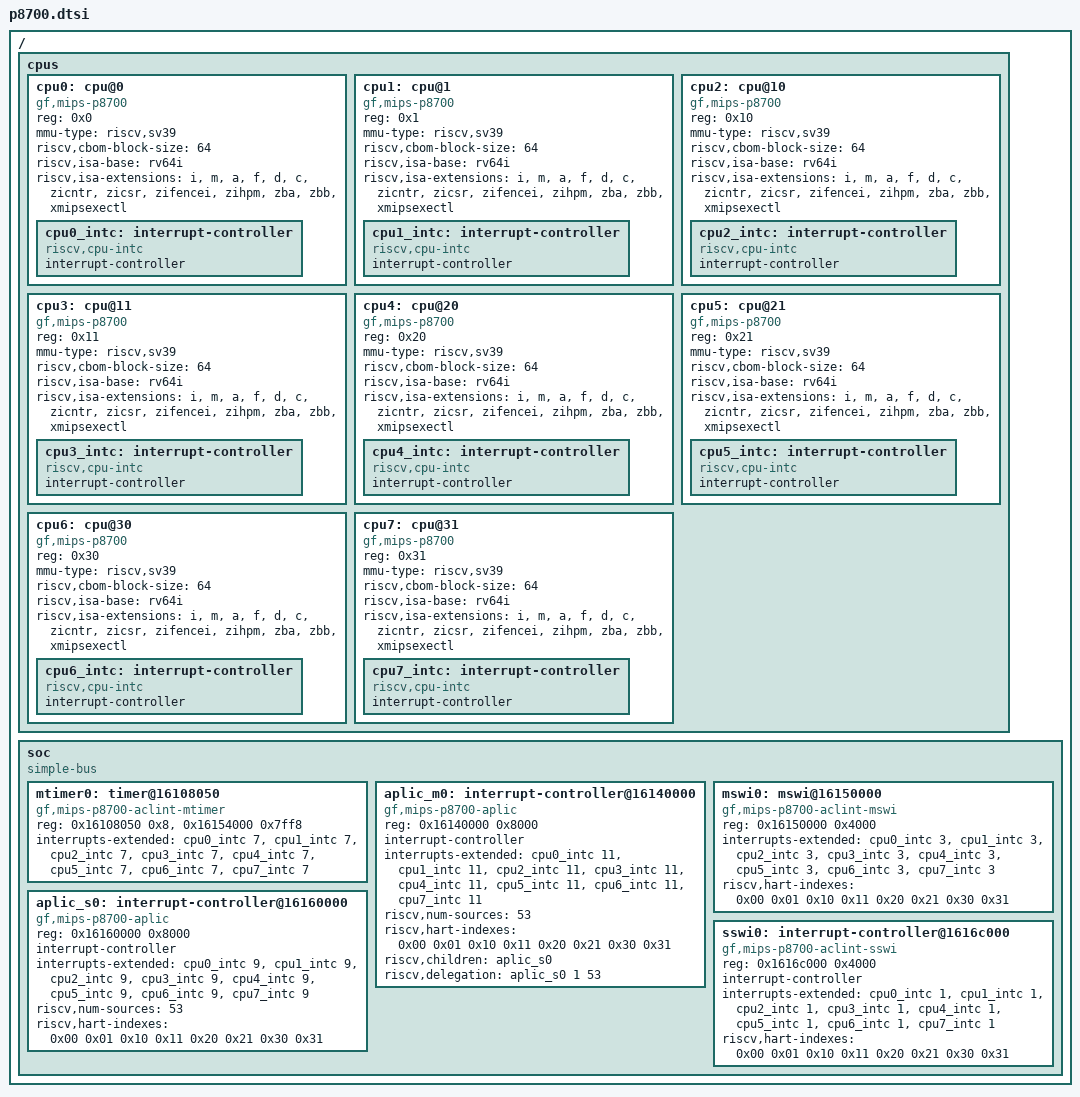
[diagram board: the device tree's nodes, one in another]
// SPDX-License-Identifier: (GPL-2.0-only OR BSD-2-Clause)
/*
 * Copyright (C) 2025 MIPS
 */

/dts-v1/;

/ {
	#address-cells = <1>;
	#size-cells = <1>;

	cpus {
		#address-cells = <1>;
		#size-cells = <0>;

		cpu0: cpu@0 {
			device_type = "cpu";
			compatible = "gf,mips-p8700", "riscv";
			reg = <0x0>;
			mmu-type = "riscv,sv39";
			riscv,cbom-block-size = <64>;
			riscv,isa-base = "rv64i";
			riscv,isa-extensions = "i", "m", "a", "f", "d", "c",
					       "zicntr", "zicsr", "zifencei",
					       "zihpm", "zba", "zbb",
					       "xmipsexectl";

			cpu0_intc: interrupt-controller {
				compatible = "riscv,cpu-intc";
				interrupt-controller;
				#interrupt-cells = <1>;
			};
		};

		cpu1: cpu@1 {
			device_type = "cpu";
			compatible = "gf,mips-p8700", "riscv";
			reg = <0x1>;
			mmu-type = "riscv,sv39";
			riscv,cbom-block-size = <64>;
			riscv,isa-base = "rv64i";
			riscv,isa-extensions = "i", "m", "a", "f", "d", "c",
					       "zicntr", "zicsr", "zifencei",
					       "zihpm", "zba", "zbb",
					       "xmipsexectl";

			cpu1_intc: interrupt-controller {
				compatible = "riscv,cpu-intc";
				interrupt-controller;
				#interrupt-cells = <1>;
			};
		};

		cpu2: cpu@10 {
			device_type = "cpu";
			compatible = "gf,mips-p8700", "riscv";
			reg = <0x10>;
			mmu-type = "riscv,sv39";
			riscv,cbom-block-size = <64>;
			riscv,isa-base = "rv64i";
			riscv,isa-extensions = "i", "m", "a", "f", "d", "c",
					       "zicntr", "zicsr", "zifencei",
					       "zihpm", "zba", "zbb",
					       "xmipsexectl";

			cpu2_intc: interrupt-controller {
				compatible = "riscv,cpu-intc";
				interrupt-controller;
				#interrupt-cells = <1>;
			};
		};

		cpu3: cpu@11 {
			device_type = "cpu";
			compatible = "gf,mips-p8700", "riscv";
			reg = <0x11>;
			mmu-type = "riscv,sv39";
			riscv,cbom-block-size = <64>;
			riscv,isa-base = "rv64i";
			riscv,isa-extensions = "i", "m", "a", "f", "d", "c",
					       "zicntr", "zicsr", "zifencei",
					       "zihpm", "zba", "zbb",
					       "xmipsexectl";

			cpu3_intc: interrupt-controller {
				compatible = "riscv,cpu-intc";
				interrupt-controller;
				#interrupt-cells = <1>;
			};
		};

		cpu4: cpu@20 {
			device_type = "cpu";
			compatible = "gf,mips-p8700", "riscv";
			reg = <0x20>;
			mmu-type = "riscv,sv39";
			riscv,cbom-block-size = <64>;
			riscv,isa-base = "rv64i";
			riscv,isa-extensions = "i", "m", "a", "f", "d", "c",
					       "zicntr", "zicsr", "zifencei",
					       "zihpm", "zba", "zbb",
					       "xmipsexectl";

			cpu4_intc: interrupt-controller {
				compatible = "riscv,cpu-intc";
				interrupt-controller;
				#interrupt-cells = <1>;
			};
		};

		cpu5: cpu@21 {
			device_type = "cpu";
			compatible = "gf,mips-p8700", "riscv";
			reg = <0x21>;
			mmu-type = "riscv,sv39";
			riscv,cbom-block-size = <64>;
			riscv,isa-base = "rv64i";
			riscv,isa-extensions = "i", "m", "a", "f", "d", "c",
					       "zicntr", "zicsr", "zifencei",
					       "zihpm", "zba", "zbb",
					       "xmipsexectl";

			cpu5_intc: interrupt-controller {
				compatible = "riscv,cpu-intc";
				interrupt-controller;
				#interrupt-cells = <1>;
			};
		};

		cpu6: cpu@30 {
			device_type = "cpu";
			compatible = "gf,mips-p8700", "riscv";
			reg = <0x30>;
			mmu-type = "riscv,sv39";
			riscv,cbom-block-size = <64>;
			riscv,isa-base = "rv64i";
			riscv,isa-extensions = "i", "m", "a", "f", "d", "c",
					       "zicntr", "zicsr", "zifencei",
					       "zihpm", "zba", "zbb",
					       "xmipsexectl";

			cpu6_intc: interrupt-controller {
				compatible = "riscv,cpu-intc";
				interrupt-controller;
				#interrupt-cells = <1>;
			};
		};

		cpu7: cpu@31 {
			device_type = "cpu";
			compatible = "gf,mips-p8700", "riscv";
			reg = <0x31>;
			mmu-type = "riscv,sv39";
			riscv,cbom-block-size = <64>;
			riscv,isa-base = "rv64i";
			riscv,isa-extensions = "i", "m", "a", "f", "d", "c",
					       "zicntr", "zicsr", "zifencei",
					       "zihpm", "zba", "zbb",
					       "xmipsexectl";

			cpu7_intc: interrupt-controller {
				compatible = "riscv,cpu-intc";
				interrupt-controller;
				#interrupt-cells = <1>;
			};
		};
	};

	soc: soc {
		compatible = "simple-bus";
		#address-cells = <1>;
		#size-cells = <1>;
		ranges;

		mtimer0: timer@16108050 {
			compatible = "gf,mips-p8700-aclint-mtimer";
			reg = <0x16108050 0x8>,
			      <0x16154000 0x7ff8>;
			reg-names = "mtime", "mtimecmp";
			interrupts-extended = <&cpu0_intc 7>, <&cpu1_intc 7>,
					      <&cpu2_intc 7>, <&cpu3_intc 7>,
					      <&cpu4_intc 7>, <&cpu5_intc 7>,
					      <&cpu6_intc 7>, <&cpu7_intc 7>;
		};

		aplic_m0: interrupt-controller@16140000 {
			compatible = "gf,mips-p8700-aplic", "riscv,aplic";
			reg = <0x16140000 0x8000>;
			interrupt-controller;
			#interrupt-cells = <2>;
			interrupts-extended = <&cpu0_intc 11>, <&cpu1_intc 11>,
					      <&cpu2_intc 11>, <&cpu3_intc 11>,
					      <&cpu4_intc 11>, <&cpu5_intc 11>,
					      <&cpu6_intc 11>, <&cpu7_intc 11>;
			riscv,num-sources = <53>;
			riscv,hart-indexes = <0x00 0x01 0x10 0x11
					      0x20 0x21 0x30 0x31>;
			riscv,children = <&aplic_s0>;
			riscv,delegation = <&aplic_s0 1 53>;
		};

		mswi0: mswi@16150000 {
			compatible = "gf,mips-p8700-aclint-mswi";
			reg = <0x16150000 0x4000>;
			interrupts-extended = <&cpu0_intc 3>, <&cpu1_intc 3>,
					      <&cpu2_intc 3>, <&cpu3_intc 3>,
					      <&cpu4_intc 3>, <&cpu5_intc 3>,
					      <&cpu6_intc 3>, <&cpu7_intc 3>;
			riscv,hart-indexes = <0x00 0x01 0x10 0x11
					      0x20 0x21 0x30 0x31>;
		};

		aplic_s0: interrupt-controller@16160000 {
			compatible = "gf,mips-p8700-aplic", "riscv,aplic";
			reg = <0x16160000 0x8000>;
			interrupt-controller;
			#interrupt-cells = <2>;
			interrupts-extended = <&cpu0_intc 9>, <&cpu1_intc 9>,
					      <&cpu2_intc 9>, <&cpu3_intc 9>,
					      <&cpu4_intc 9>, <&cpu5_intc 9>,
					      <&cpu6_intc 9>, <&cpu7_intc 9>;
			riscv,num-sources = <53>;
			riscv,hart-indexes = <0x00 0x01 0x10 0x11
					      0x20 0x21 0x30 0x31>;
		};

		sswi0: interrupt-controller@1616c000 {
			compatible = "gf,mips-p8700-aclint-sswi",
				     "mips,p8700-aclint-sswi";
			reg = <0x1616c000 0x4000>;
			interrupt-controller;
			#interrupt-cells = <0>;
			interrupts-extended = <&cpu0_intc 1>, <&cpu1_intc 1>,
					      <&cpu2_intc 1>, <&cpu3_intc 1>,
					      <&cpu4_intc 1>, <&cpu5_intc 1>,
					      <&cpu6_intc 1>, <&cpu7_intc 1>;
			riscv,hart-indexes = <0x00 0x01 0x10 0x11
					      0x20 0x21 0x30 0x31>;
		};
	};
};
